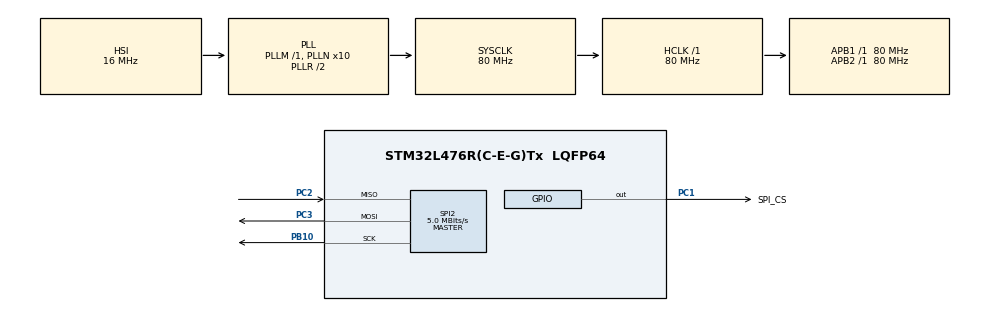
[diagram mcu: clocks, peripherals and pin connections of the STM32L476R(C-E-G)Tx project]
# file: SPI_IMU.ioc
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Dma.Request0=SPI2_RX
Dma.Request1=SPI2_TX
Dma.SPI2_RX.0.Direction=DMA_PERIPH_TO_MEMORY
Dma.SPI2_RX.0.Instance=DMA1_Channel4
Dma.SPI2_RX.0.MemDataAlignment=DMA_MDATAALIGN_BYTE
Dma.SPI2_RX.0.MemInc=DMA_MINC_ENABLE
Dma.SPI2_RX.0.Mode=DMA_NORMAL
Dma.SPI2_RX.0.PeriphDataAlignment=DMA_PDATAALIGN_BYTE
Dma.SPI2_RX.0.PeriphInc=DMA_PINC_DISABLE
Dma.SPI2_RX.0.Priority=DMA_PRIORITY_LOW
Dma.SPI2_TX.1.Direction=DMA_MEMORY_TO_PERIPH
Dma.SPI2_TX.1.Instance=DMA1_Channel5
Dma.SPI2_TX.1.MemDataAlignment=DMA_MDATAALIGN_BYTE
Dma.SPI2_TX.1.MemInc=DMA_MINC_ENABLE
Dma.SPI2_TX.1.Mode=DMA_NORMAL
Dma.SPI2_TX.1.PeriphDataAlignment=DMA_PDATAALIGN_BYTE
Dma.SPI2_TX.1.PeriphInc=DMA_PINC_DISABLE
Dma.SPI2_TX.1.Priority=DMA_PRIORITY_LOW
Mcu.Family=STM32L4
Mcu.Name=STM32L476R(C-E-G)Tx
Mcu.Package=LQFP64
NVIC.DMA1_Channel4_IRQn=true\:0\:0\:false\:false\:true\:false\:true\:true
NVIC.DMA1_Channel5_IRQn=true\:0\:0\:false\:false\:true\:false\:true\:true
NVIC.PriorityGroup=NVIC_PRIORITYGROUP_4
NVIC.SPI2_IRQn=true\:0\:0\:false\:false\:true\:true\:true\:true
PA13\ (JTMS-SWDIO).Mode=Serial_Wire
PA13\ (JTMS-SWDIO).Signal=SYS_JTMS-SWDIO
PA14\ (JTCK-SWCLK).Mode=Serial_Wire
PA14\ (JTCK-SWCLK).Signal=SYS_JTCK-SWCLK
PB10.Mode=Full_Duplex_Master
PB10.Signal=SPI2_SCK
PC1.GPIO_Label=SPI_CS
PC1.Signal=GPIO_Output
PC2.Mode=Full_Duplex_Master
PC2.Signal=SPI2_MISO
PC3.Mode=Full_Duplex_Master
PC3.Signal=SPI2_MOSI
ProjectManager.HeapSize=0x200
ProjectManager.StackSize=0x400
ProjectManager.TargetToolchain=MDK-ARM V5.32
RCC.ADCFreq_Value=64000000
RCC.AHBFreq_Value=80000000
RCC.APB1Freq_Value=80000000
RCC.APB1TimFreq_Value=80000000
RCC.APB2Freq_Value=80000000
RCC.APB2TimFreq_Value=80000000
RCC.CortexFreq_Value=80000000
RCC.HCLKFreq_Value=80000000
RCC.HSE_VALUE=8000000
RCC.HSI_VALUE=16000000
RCC.LSE_VALUE=32768
RCC.MSI_VALUE=4000000
RCC.PLLN=10
RCC.PLLSourceVirtual=RCC_PLLSOURCE_HSI
RCC.SYSCLKFreq_VALUE=80000000
RCC.SYSCLKSource=RCC_SYSCLKSOURCE_PLLCLK
RCC.USBFreq_Value=64000000
RCC.VCOOutputFreq_Value=160000000
SPI2.BaudRatePrescaler=SPI_BAUDRATEPRESCALER_16
SPI2.CLKPhase=SPI_PHASE_2EDGE
SPI2.CLKPolarity=SPI_POLARITY_HIGH
SPI2.CalculateBaudRate=5.0 MBits/s
SPI2.DataSize=SPI_DATASIZE_8BIT
SPI2.Direction=SPI_DIRECTION_2LINES
SPI2.Mode=SPI_MODE_MASTER
SPI2.VirtualType=VM_MASTER
board=custom

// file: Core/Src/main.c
/* USER CODE BEGIN Header */
/**
  ******************************************************************************
  * @file           : main.c
  * @brief          : Main program body
  ******************************************************************************
  * @attention
  *
  * Copyright (c) 2026 STMicroelectronics.
  * All rights reserved.
  *
  * This software is licensed under terms that can be found in the LICENSE file
  * in the root directory of this software component.
  * If no LICENSE file comes with this software, it is provided AS-IS.
  *
  ******************************************************************************
  */
/* USER CODE END Header */
#include "main.h"

/* USER CODE BEGIN Includes */
#include "icm_20948.h"
/* USER CODE END Includes */

/* USER CODE BEGIN PTD */
uint8_t address;
icm_20948_data thongtin;
/* USER CODE END PTD */

SPI_HandleTypeDef hspi2;
DMA_HandleTypeDef hdma_spi2_rx;
DMA_HandleTypeDef hdma_spi2_tx;

void SystemClock_Config(void);
static void MX_GPIO_Init(void);
static void MX_DMA_Init(void);
static void MX_SPI2_Init(void);

int main(void)
{

  /* MCU Configuration--------------------------------------------------------*/

  /* Reset of all peripherals, Initializes the Flash interface and the Systick. */
  HAL_Init();

  /* Configure the system clock */
  SystemClock_Config();

  /* Initialize all configured peripherals */
  MX_GPIO_Init();
  MX_DMA_Init();
  MX_SPI2_Init();
  /* USER CODE BEGIN 2 */
	icm_20948_init();
	icm_20948_start_read();
  /* USER CODE END 2 */

  /* Infinite loop */
  while (1)
  {

    /* USER CODE BEGIN 3 */
		icm_20948_process();

		if (imu_state == IMU_STATE_DATA_READY)
		{
			icm_20948_read_data(&thongtin);
			icm_20948_start_read();
		}
  }
  /* USER CODE END 3 */
}

void SystemClock_Config(void)
{
  RCC_OscInitTypeDef RCC_OscInitStruct = {0};
  RCC_ClkInitTypeDef RCC_ClkInitStruct = {0};

  /** Configure the main internal regulator output voltage
  */
  if (HAL_PWREx_ControlVoltageScaling(PWR_REGULATOR_VOLTAGE_SCALE1) != HAL_OK)
  {
    Error_Handler();
  }

  /** Initializes the RCC Oscillators according to the specified parameters
  * in the RCC_OscInitTypeDef structure.
  */
  RCC_OscInitStruct.OscillatorType = RCC_OSCILLATORTYPE_HSI;
  RCC_OscInitStruct.HSIState = RCC_HSI_ON;
  RCC_OscInitStruct.HSICalibrationValue = RCC_HSICALIBRATION_DEFAULT;
  RCC_OscInitStruct.PLL.PLLState = RCC_PLL_ON;
  RCC_OscInitStruct.PLL.PLLSource = RCC_PLLSOURCE_HSI;
  RCC_OscInitStruct.PLL.PLLM = 1;
  RCC_OscInitStruct.PLL.PLLN = 10;
  RCC_OscInitStruct.PLL.PLLP = RCC_PLLP_DIV7;
  RCC_OscInitStruct.PLL.PLLQ = RCC_PLLQ_DIV2;
  RCC_OscInitStruct.PLL.PLLR = RCC_PLLR_DIV2;
  if (HAL_RCC_OscConfig(&RCC_OscInitStruct) != HAL_OK)
  {
    Error_Handler();
  }

  /** Initializes the CPU, AHB and APB buses clocks
  */
  RCC_ClkInitStruct.ClockType = RCC_CLOCKTYPE_HCLK|RCC_CLOCKTYPE_SYSCLK
                              |RCC_CLOCKTYPE_PCLK1|RCC_CLOCKTYPE_PCLK2;
  RCC_ClkInitStruct.SYSCLKSource = RCC_SYSCLKSOURCE_PLLCLK;
  RCC_ClkInitStruct.AHBCLKDivider = RCC_SYSCLK_DIV1;
  RCC_ClkInitStruct.APB1CLKDivider = RCC_HCLK_DIV1;
  RCC_ClkInitStruct.APB2CLKDivider = RCC_HCLK_DIV1;

  if (HAL_RCC_ClockConfig(&RCC_ClkInitStruct, FLASH_LATENCY_4) != HAL_OK)
  {
    Error_Handler();
  }
}

static void MX_SPI2_Init(void)
{

  /* SPI2 parameter configuration*/
  hspi2.Instance = SPI2;
  hspi2.Init.Mode = SPI_MODE_MASTER;
  hspi2.Init.Direction = SPI_DIRECTION_2LINES;
  hspi2.Init.DataSize = SPI_DATASIZE_8BIT;
  hspi2.Init.CLKPolarity = SPI_POLARITY_HIGH;
  hspi2.Init.CLKPhase = SPI_PHASE_2EDGE;
  hspi2.Init.NSS = SPI_NSS_SOFT;
  hspi2.Init.BaudRatePrescaler = SPI_BAUDRATEPRESCALER_16;
  hspi2.Init.FirstBit = SPI_FIRSTBIT_MSB;
  hspi2.Init.TIMode = SPI_TIMODE_DISABLE;
  hspi2.Init.CRCCalculation = SPI_CRCCALCULATION_DISABLE;
  hspi2.Init.CRCPolynomial = 7;
  hspi2.Init.CRCLength = SPI_CRC_LENGTH_DATASIZE;
  hspi2.Init.NSSPMode = SPI_NSS_PULSE_DISABLE;
  if (HAL_SPI_Init(&hspi2) != HAL_OK)
  {
    Error_Handler();
  }

}

static void MX_DMA_Init(void)
{

  /* DMA controller clock enable */
  __HAL_RCC_DMA1_CLK_ENABLE();

  /* DMA interrupt init */
  /* DMA1_Channel4_IRQn interrupt configuration */
  HAL_NVIC_SetPriority(DMA1_Channel4_IRQn, 0, 0);
  HAL_NVIC_EnableIRQ(DMA1_Channel4_IRQn);
  /* DMA1_Channel5_IRQn interrupt configuration */
  HAL_NVIC_SetPriority(DMA1_Channel5_IRQn, 0, 0);
  HAL_NVIC_EnableIRQ(DMA1_Channel5_IRQn);

}

static void MX_GPIO_Init(void)
{
  GPIO_InitTypeDef GPIO_InitStruct = {0};

  /* GPIO Ports Clock Enable */
  __HAL_RCC_GPIOC_CLK_ENABLE();
  __HAL_RCC_GPIOB_CLK_ENABLE();
  __HAL_RCC_GPIOA_CLK_ENABLE();

  /*Configure GPIO pin Output Level */
  HAL_GPIO_WritePin(SPI_CS_GPIO_Port, SPI_CS_Pin, GPIO_PIN_RESET);

  /*Configure GPIO pin : SPI_CS_Pin */
  GPIO_InitStruct.Pin = SPI_CS_Pin;
  GPIO_InitStruct.Mode = GPIO_MODE_OUTPUT_PP;
  GPIO_InitStruct.Pull = GPIO_NOPULL;
  GPIO_InitStruct.Speed = GPIO_SPEED_FREQ_LOW;
  HAL_GPIO_Init(SPI_CS_GPIO_Port, &GPIO_InitStruct);

}

void Error_Handler(void)
{
  __disable_irq();
  while (1)
  {
  }
}
